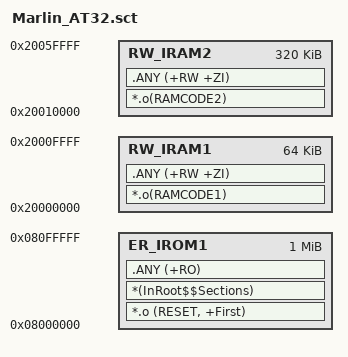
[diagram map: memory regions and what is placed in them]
LR_IROM1 0x08000000 0x00100000 {
  ER_IROM1 0x08000000 0x00100000 {
   *.o (RESET, +First)
   *(InRoot$$Sections)
   .ANY (+RO)
  }

  RW_IRAM1 0x20000000 0x00010000 {
    *.o(RAMCODE1)
   .ANY (+RW +ZI)
  }

  RW_IRAM2 0x20010000 0x00050000 {
	*.o(RAMCODE2)
   .ANY (+RW +ZI)
  }
}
